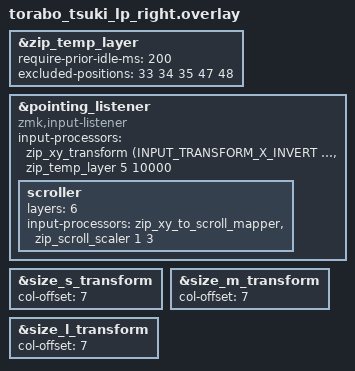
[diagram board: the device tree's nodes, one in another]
#include "torabo_tsuki_lp.dtsi"
#include <input/processors.dtsi>
#include <dt-bindings/zmk/input_transform.h>

&zip_temp_layer {
    //キー入力から200ms間はAMLを発動しない。
    require-prior-idle-ms = <200>;

    //下記以外のキーを押すとAMLを解除する。
    excluded-positions = <
        33 // J
        34 // K
        35 // L
        47 // M
        48 // <
    >;
};


&pointing_listener {
    compatible = "zmk,input-listener";
    input-processors =
        <&zip_xy_transform (INPUT_TRANSFORM_X_INVERT | INPUT_TRANSFORM_Y_INVERT)>,
        //トラボ使用後10秒間レイヤー5を有効にする。
        <&zip_temp_layer 5 10000>;

    // 【レイヤー別設定】レイヤー6が有効な時だけ、カーソル移動をスクロールに変換する
    scroller {
        layers = <6>;
        input-processors = <
            &zip_xy_to_scroll_mapper
            &zip_scroll_scaler 1 3
        >;
    };
};

&size_s_transform {
    col-offset = <7>;
};

&size_m_transform {
    col-offset = <7>;
};

&size_l_transform {
    col-offset = <7>;
};
